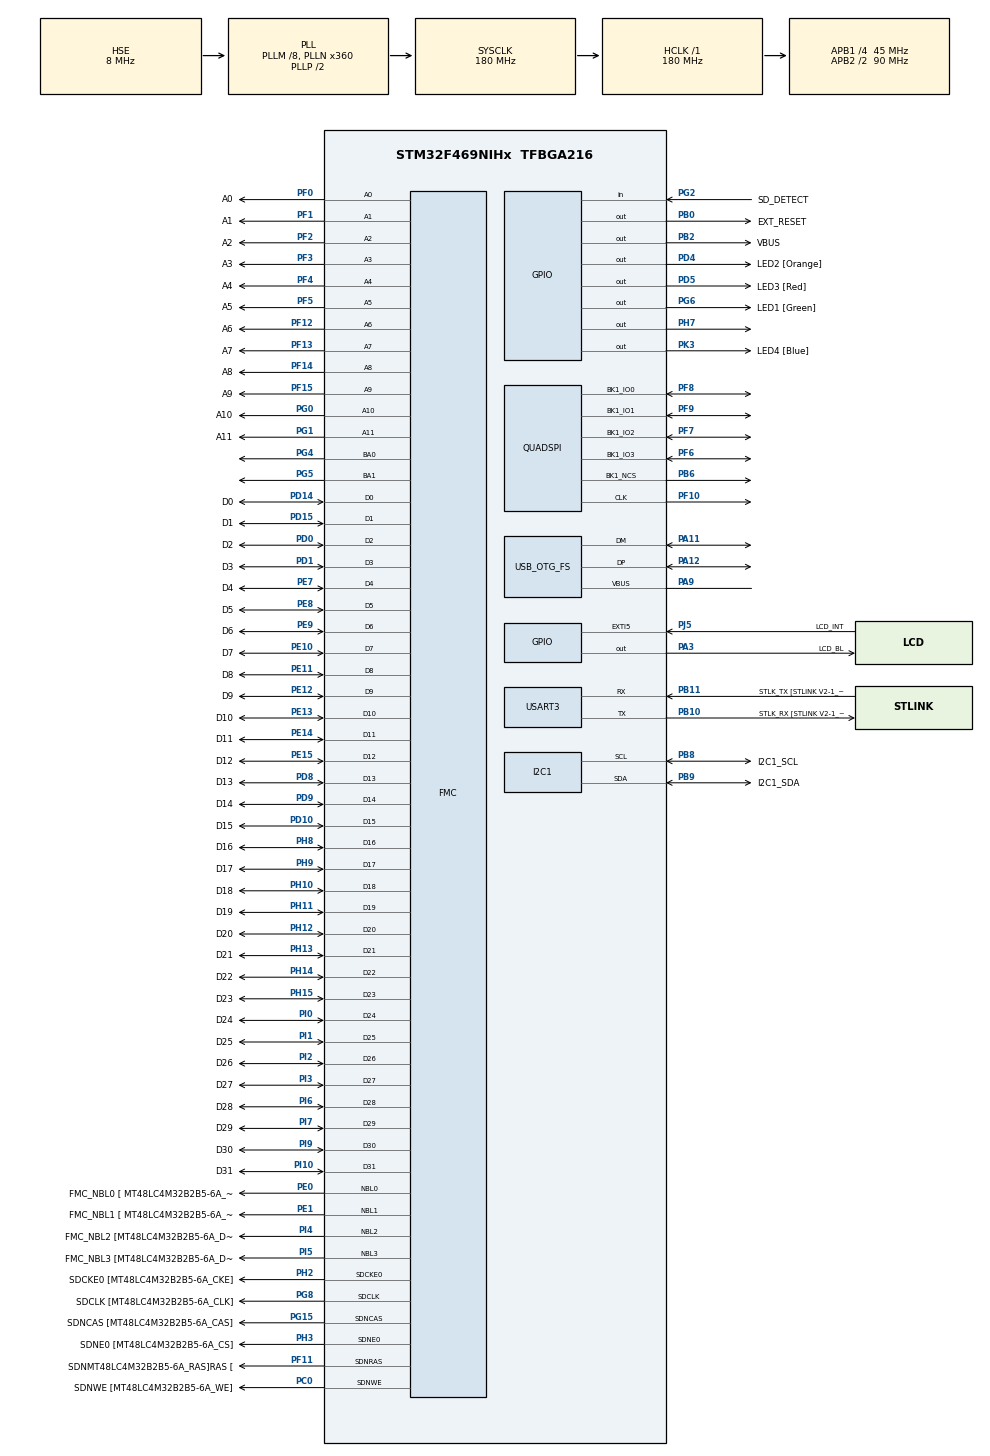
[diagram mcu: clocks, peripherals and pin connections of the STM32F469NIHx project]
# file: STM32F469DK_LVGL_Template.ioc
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DMA2D.ColorMode=DMA2D_OUTPUT_RGB565
DSIHOST.BTA_FlowControl=__NULL
DSIHOST.ClockLaneHS2LPTime=35
DSIHOST.ClockLaneLP2HSTime=35
DSIHOST.DataLaneHS2LPTime=35
DSIHOST.DataLaneLP2HSTime=35
DSIHOST.LPCommandEnable=DSI_LP_COMMAND_ENABLE
DSIHOST.LPHorizontalBackPorchEnable=DSI_LP_HBP_ENABLE
DSIHOST.LPHorizontalFrontPorchEnable=DSI_LP_HFP_ENABLE
DSIHOST.LPLargestPacketSize=16
DSIHOST.LPVerticalActiveEnable=DSI_LP_VACT_ENABLE
DSIHOST.LPVerticalBackPorchEnable=DSI_LP_VBP_ENABLE
DSIHOST.LPVerticalFrontPorchEnable=DSI_LP_VFP_ENABLE
DSIHOST.LPVerticalSyncActiveEnable=DSI_LP_VSYNC_ENABLE
DSIHOST.Mode=DSI_VID_MODE_BURST
DSIHOST.NumberOfLanes=DSI_TWO_DATA_LANES
DSIHOST.PacketSize=800
DSIHOST.StopWaitTime=10
DSIHOST_CKN.GPIO_Label=DSI_CK_N
DSIHOST_CKN.Mode=DSIHost_Video
DSIHOST_CKN.Signal=DSIHOST_CKN
DSIHOST_CKP.GPIO_Label=DSI_CK_P
DSIHOST_CKP.Mode=DSIHost_Video
DSIHOST_CKP.Signal=DSIHOST_CKP
DSIHOST_D0N.GPIO_Label=DSI_D0_N
DSIHOST_D0N.Mode=DSIHost_Video
DSIHOST_D0N.Signal=DSIHOST_D0N
DSIHOST_D0P.GPIO_Label=DSI_D0_P
DSIHOST_D0P.Mode=DSIHost_Video
DSIHOST_D0P.Signal=DSIHOST_D0P
DSIHOST_D1N.GPIO_Label=DSI_D1_N
DSIHOST_D1N.Mode=DSIHost_Video
DSIHOST_D1N.Signal=DSIHOST_D1N
DSIHOST_D1P.GPIO_Label=DSI_D1_P
DSIHOST_D1P.Mode=DSIHost_Video
DSIHOST_D1P.Signal=DSIHOST_D1P
Dma.MEMTOMEM.0.Direction=DMA_MEMORY_TO_MEMORY
Dma.MEMTOMEM.0.FIFOMode=DMA_FIFOMODE_ENABLE
Dma.MEMTOMEM.0.FIFOThreshold=DMA_FIFO_THRESHOLD_FULL
Dma.MEMTOMEM.0.Instance=DMA2_Stream0
Dma.MEMTOMEM.0.MemBurst=DMA_MBURST_SINGLE
Dma.MEMTOMEM.0.MemDataAlignment=DMA_MDATAALIGN_WORD
Dma.MEMTOMEM.0.MemInc=DMA_MINC_ENABLE
Dma.MEMTOMEM.0.Mode=DMA_NORMAL
Dma.MEMTOMEM.0.PeriphBurst=DMA_PBURST_SINGLE
Dma.MEMTOMEM.0.PeriphDataAlignment=DMA_PDATAALIGN_WORD
Dma.MEMTOMEM.0.PeriphInc=DMA_PINC_ENABLE
Dma.MEMTOMEM.0.Priority=DMA_PRIORITY_LOW
Dma.Request0=MEMTOMEM
FATFS._FS_EXFAT=1
FATFS._FS_TINY=0
FATFS._MAX_SS=4096
FATFS._USE_LFN=2
FATFS._USE_MUTEX=0
FMC.CASLatency1=FMC_SDRAM_CAS_LATENCY_3
FMC.ExitSelfRefreshDelay1=7
FMC.LoadToActiveDelay1=2
FMC.RCDDelay1=2
FMC.RPDelay1=2
FMC.RPDelay2=2
FMC.ReadBurst1=FMC_SDRAM_RBURST_ENABLE
FMC.ReadBurst2=FMC_SDRAM_RBURST_ENABLE
FMC.RowCycleDelay1=7
FMC.RowCycleDelay2=7
FMC.SDClockPeriod1=FMC_SDRAM_CLOCK_PERIOD_2
FMC.SDClockPeriod2=FMC_SDRAM_CLOCK_PERIOD_2
FMC.SelfRefreshTime1=4
FMC.WriteRecoveryTime1=3
FREERTOS.Tasks01=mainTask,0,2048,MainTask,As weak,NULL,Dynamic,NULL,NULL;gfxTask,-2,1024,GfxTask,As external,NULL,Dynamic,NULL,NULL;rtTask,3,256,RTTask,As external,NULL,Dynamic,NULL,NULL
FREERTOS.configMINIMAL_STACK_SIZE=256
FREERTOS.configTOTAL_HEAP_SIZE=32787
FREERTOS.configUSE_NEWLIB_REENTRANT=1
LTDC.ActiveW=800
LTDC.Alpha_L0=255
LTDC.BlendingFactor1_L0=LTDC_BLENDING_FACTOR1_PAxCA
LTDC.BlendingFactor2_L0=LTDC_BLENDING_FACTOR2_PAxCA
LTDC.FBStartAdress_L0=0xC0000000
LTDC.HBP=34
LTDC.HFP=34
LTDC.HSPolarity=LTDC_HSPOLARITY_AH
LTDC.HSync=2
LTDC.ImageHeight_L0=480
LTDC.ImageWidth_L0=800
LTDC.Layers=0
LTDC.PixelFormat_L0=LTDC_PIXEL_FORMAT_RGB565
LTDC.VBP=150
LTDC.VFP=150
LTDC.VSPolarity=LTDC_VSPOLARITY_AH
LTDC.VSync=120
LTDC.WindowX1_L0=800
LTDC.WindowY1_L0=480
Mcu.Family=STM32F4
Mcu.Name=STM32F469NIHx
Mcu.Package=TFBGA216
NVIC.DMA2D_IRQn=true\:5\:0\:false\:false\:true\:true\:true\:true\:true
NVIC.DMA2_Stream0_IRQn=true\:5\:0\:false\:false\:true\:true\:true\:true\:true
NVIC.DSI_IRQn=true\:5\:0\:false\:false\:true\:true\:true\:true\:true
NVIC.LTDC_IRQn=true\:5\:0\:false\:false\:true\:true\:true\:true\:true
NVIC.OTG_FS_IRQn=true\:5\:0\:false\:false\:true\:true\:true\:true\:true
NVIC.PriorityGroup=NVIC_PRIORITYGROUP_4
NVIC.TIM7_IRQn=true\:3\:0\:true\:false\:true\:false\:false\:true\:true
NVIC.TimeBase=TIM7_IRQn
NVIC.TimeBaseIP=TIM7
PA0/WKUP.GPIO_Label=WAKEUP [B2]
PA0/WKUP.Mode=SYS_WakeUp0
PA0/WKUP.Signal=SYS_WKUP
PA11.Mode=Host_Only
PA11.Signal=USB_OTG_FS_DM
PA12.Mode=Host_Only
PA12.Signal=USB_OTG_FS_DP
PA13.GPIO_Label=SWDIO
PA13.Mode=Serial_Wire
PA13.Signal=SYS_JTMS-SWDIO
PA14.GPIO_Label=SWCLK
PA14.Mode=Serial_Wire
PA14.Signal=SYS_JTCK-SWCLK
PA3.GPIO_Label=LCD_BL
PA3.Signal=GPIO_Output
PA9.Mode=Activate_VBUS
PA9.Signal=USB_OTG_FS_VBUS
PB0.GPIO_Label=EXT_RESET
PB0.GPIO_ModeDefaultOutputPP=GPIO_MODE_OUTPUT_PP
PB0.GPIO_PuPd=GPIO_NOPULL
PB0.GPIO_Speed=GPIO_SPEED_FREQ_LOW
PB0.Signal=GPIO_Output
PB10.GPIO_Label=STLK_RX [STLINK V2-1_U2_RX]
PB10.GPIO_Mode=GPIO_MODE_AF_PP
PB10.GPIO_PuPd=GPIO_PULLUP
PB10.GPIO_Speed=GPIO_SPEED_FREQ_VERY_HIGH
PB10.Mode=Asynchronous
PB10.Signal=USART3_TX
PB11.GPIO_Label=STLK_TX [STLINK V2-1_U2_TX]
PB11.GPIO_Mode=GPIO_MODE_AF_PP
PB11.GPIO_PuPd=GPIO_PULLUP
PB11.GPIO_Speed=GPIO_SPEED_FREQ_VERY_HIGH
PB11.Mode=Asynchronous
PB11.Signal=USART3_RX
PB2/BOOT1.GPIO_Label=VBUS
PB2/BOOT1.GPIO_ModeDefaultOutputPP=GPIO_MODE_OUTPUT_PP
PB2/BOOT1.GPIO_PuPd=GPIO_NOPULL
PB2/BOOT1.GPIO_Speed=GPIO_SPEED_FREQ_LOW
PB2/BOOT1.PinState=GPIO_PIN_SET
PB2/BOOT1.Signal=GPIO_Output
PB6.Mode=Single Bank 1
PB6.Signal=QUADSPI_BK1_NCS
PB8.GPIO_Label=I2C1_SCL
PB8.GPIO_Mode=GPIO_MODE_AF_OD
PB8.GPIO_Pu=GPIO_PULLUP
PB8.GPIO_Speed=GPIO_SPEED_FREQ_VERY_HIGH
PB8.Mode=I2C
PB8.Signal=I2C1_SCL
PB9.GPIO_Label=I2C1_SDA
PB9.GPIO_Mode=GPIO_MODE_AF_OD
PB9.GPIO_Pu=GPIO_PULLUP
PB9.GPIO_Speed=GPIO_SPEED_FREQ_VERY_HIGH
PB9.Mode=I2C
PB9.Signal=I2C1_SDA
PC0.GPIO_Label=SDNWE [MT48LC4M32B2B5-6A_WE]
PC0.GPIO_Mode=GPIO_MODE_AF_PP
PC0.GPIO_PuPd=GPIO_NOPULL
PC0.GPIO_Speed_High_Default=GPIO_SPEED_FREQ_VERY_HIGH
PC0.Signal=FMC_SDNWE
PC14/OSC32_IN.Mode=LSE-External-Oscillator
PC14/OSC32_IN.Signal=RCC_OSC32_IN
PC15/OSC32_OUT.Mode=LSE-External-Oscillator
PC15/OSC32_OUT.Signal=RCC_OSC32_OUT
PD0.GPIO_Label=D2
PD0.GPIO_Mode=GPIO_MODE_AF_PP
PD0.GPIO_PuPd=GPIO_NOPULL
PD0.GPIO_Speed_High_Default=GPIO_SPEED_FREQ_VERY_HIGH
PD0.Signal=FMC_D2_DA2
PD1.GPIO_Label=D3
PD1.GPIO_Mode=GPIO_MODE_AF_PP
PD1.GPIO_PuPd=GPIO_NOPULL
PD1.GPIO_Speed_High_Default=GPIO_SPEED_FREQ_VERY_HIGH
PD1.Signal=FMC_D3_DA3
PD10.GPIO_Label=D15
PD10.GPIO_Mode=GPIO_MODE_AF_PP
PD10.GPIO_PuPd=GPIO_NOPULL
PD10.GPIO_Speed_High_Default=GPIO_SPEED_FREQ_VERY_HIGH
PD10.Signal=FMC_D15_DA15
PD14.GPIO_Label=D0
PD14.GPIO_Mode=GPIO_MODE_AF_PP
PD14.GPIO_PuPd=GPIO_NOPULL
PD14.GPIO_Speed_High_Default=GPIO_SPEED_FREQ_VERY_HIGH
PD14.Signal=FMC_D0_DA0
PD15.GPIO_Label=D1
PD15.GPIO_Mode=GPIO_MODE_AF_PP
PD15.GPIO_PuPd=GPIO_NOPULL
PD15.GPIO_Speed_High_Default=GPIO_SPEED_FREQ_VERY_HIGH
PD15.Signal=FMC_D1_DA1
PD4.GPIO_Label=LED2 [Orange]
PD4.GPIO_ModeDefaultOutputPP=GPIO_MODE_OUTPUT_OD
PD4.GPIO_PuPd=GPIO_NOPULL
PD4.GPIO_Speed=GPIO_SPEED_FREQ_LOW
PD4.Signal=GPIO_Output
PD5.GPIO_Label=LED3 [Red]
PD5.GPIO_ModeDefaultOutputPP=GPIO_MODE_OUTPUT_OD
PD5.GPIO_PuPd=GPIO_NOPULL
PD5.GPIO_Speed=GPIO_SPEED_FREQ_LOW
PD5.Signal=GPIO_Output
PD8.GPIO_Label=D13
PD8.GPIO_Mode=GPIO_MODE_AF_PP
PD8.GPIO_PuPd=GPIO_NOPULL
PD8.GPIO_Speed_High_Default=GPIO_SPEED_FREQ_VERY_HIGH
PD8.Signal=FMC_D13_DA13
PD9.GPIO_Label=D14
PD9.GPIO_Mode=GPIO_MODE_AF_PP
PD9.GPIO_PuPd=GPIO_NOPULL
PD9.GPIO_Speed_High_Default=GPIO_SPEED_FREQ_VERY_HIGH
PD9.Signal=FMC_D14_DA14
PE0.GPIO_Label=FMC_NBL0 [ MT48LC4M32B2B5-6A_DQM0]
PE0.GPIO_Mode=GPIO_MODE_AF_PP
PE0.GPIO_PuPd=GPIO_NOPULL
PE0.GPIO_Speed_High_Default=GPIO_SPEED_FREQ_VERY_HIGH
PE0.Signal=FMC_NBL0
PE1.GPIO_Label=FMC_NBL1 [ MT48LC4M32B2B5-6A_DQM1]
PE1.GPIO_Mode=GPIO_MODE_AF_PP
PE1.GPIO_PuPd=GPIO_NOPULL
PE1.GPIO_Speed_High_Default=GPIO_SPEED_FREQ_VERY_HIGH
PE1.Signal=FMC_NBL1
PE10.GPIO_Label=D7
PE10.GPIO_Mode=GPIO_MODE_AF_PP
PE10.GPIO_PuPd=GPIO_NOPULL
PE10.GPIO_Speed_High_Default=GPIO_SPEED_FREQ_VERY_HIGH
PE10.Signal=FMC_D7_DA7
PE11.GPIO_Label=D8
PE11.GPIO_Mode=GPIO_MODE_AF_PP
PE11.GPIO_PuPd=GPIO_NOPULL
PE11.GPIO_Speed_High_Default=GPIO_SPEED_FREQ_VERY_HIGH
PE11.Signal=FMC_D8_DA8
PE12.GPIO_Label=D9
PE12.GPIO_Mode=GPIO_MODE_AF_PP
PE12.GPIO_PuPd=GPIO_NOPULL
PE12.GPIO_Speed_High_Default=GPIO_SPEED_FREQ_VERY_HIGH
PE12.Signal=FMC_D9_DA9
PE13.GPIO_Label=D10
PE13.GPIO_Mode=GPIO_MODE_AF_PP
PE13.GPIO_PuPd=GPIO_NOPULL
PE13.GPIO_Speed_High_Default=GPIO_SPEED_FREQ_VERY_HIGH
PE13.Signal=FMC_D10_DA10
PE14.GPIO_Label=D11
PE14.GPIO_Mode=GPIO_MODE_AF_PP
PE14.GPIO_PuPd=GPIO_NOPULL
PE14.GPIO_Speed_High_Default=GPIO_SPEED_FREQ_VERY_HIGH
PE14.Signal=FMC_D11_DA11
PE15.GPIO_Label=D12
PE15.GPIO_Mode=GPIO_MODE_AF_PP
PE15.GPIO_PuPd=GPIO_NOPULL
PE15.GPIO_Speed_High_Default=GPIO_SPEED_FREQ_VERY_HIGH
PE15.Signal=FMC_D12_DA12
PE7.GPIO_Label=D4
PE7.GPIO_Mode=GPIO_MODE_AF_PP
PE7.GPIO_PuPd=GPIO_NOPULL
PE7.GPIO_Speed_High_Default=GPIO_SPEED_FREQ_VERY_HIGH
PE7.Signal=FMC_D4_DA4
PE8.GPIO_Label=D5
PE8.GPIO_Mode=GPIO_MODE_AF_PP
PE8.GPIO_PuPd=GPIO_NOPULL
PE8.GPIO_Speed_High_Default=GPIO_SPEED_FREQ_VERY_HIGH
PE8.Signal=FMC_D5_DA5
PE9.GPIO_Label=D6
PE9.GPIO_Mode=GPIO_MODE_AF_PP
PE9.GPIO_PuPd=GPIO_NOPULL
PE9.GPIO_Speed_High_Default=GPIO_SPEED_FREQ_VERY_HIGH
PE9.Signal=FMC_D6_DA6
PF0.GPIO_Label=A0
PF0.GPIO_Mode=GPIO_MODE_AF_PP
PF0.GPIO_PuPd=GPIO_NOPULL
PF0.GPIO_Speed_High_Default=GPIO_SPEED_FREQ_VERY_HIGH
PF0.Signal=FMC_A0
PF1.GPIO_Label=A1
PF1.GPIO_Mode=GPIO_MODE_AF_PP
PF1.GPIO_PuPd=GPIO_NOPULL
PF1.GPIO_Speed_High_Default=GPIO_SPEED_FREQ_VERY_HIGH
PF1.Signal=FMC_A1
PF10.Mode=Single Bank 1
PF10.Signal=QUADSPI_CLK
PF11.GPIO_Label=SDNMT48LC4M32B2B5-6A_RAS]RAS [
PF11.GPIO_Mode=GPIO_MODE_AF_PP
PF11.GPIO_PuPd=GPIO_NOPULL
PF11.GPIO_Speed_High_Default=GPIO_SPEED_FREQ_VERY_HIGH
PF11.Signal=FMC_SDNRAS
PF12.GPIO_Label=A6
PF12.GPIO_Mode=GPIO_MODE_AF_PP
PF12.GPIO_PuPd=GPIO_NOPULL
PF12.GPIO_Speed_High_Default=GPIO_SPEED_FREQ_VERY_HIGH
PF12.Signal=FMC_A6
PF13.GPIO_Label=A7
PF13.GPIO_Mode=GPIO_MODE_AF_PP
PF13.GPIO_PuPd=GPIO_NOPULL
PF13.GPIO_Speed_High_Default=GPIO_SPEED_FREQ_VERY_HIGH
PF13.Signal=FMC_A7
PF14.GPIO_Label=A8
PF14.GPIO_Mode=GPIO_MODE_AF_PP
PF14.GPIO_PuPd=GPIO_NOPULL
PF14.GPIO_Speed_High_Default=GPIO_SPEED_FREQ_VERY_HIGH
PF14.Signal=FMC_A8
PF15.GPIO_Label=A9
PF15.GPIO_Mode=GPIO_MODE_AF_PP
PF15.GPIO_PuPd=GPIO_NOPULL
PF15.GPIO_Speed_High_Default=GPIO_SPEED_FREQ_VERY_HIGH
PF15.Signal=FMC_A9
PF2.GPIO_Label=A2
PF2.GPIO_Mode=GPIO_MODE_AF_PP
PF2.GPIO_PuPd=GPIO_NOPULL
PF2.GPIO_Speed_High_Default=GPIO_SPEED_FREQ_VERY_HIGH
PF2.Signal=FMC_A2
PF3.GPIO_Label=A3
PF3.GPIO_Mode=GPIO_MODE_AF_PP
PF3.GPIO_PuPd=GPIO_NOPULL
PF3.GPIO_Speed_High_Default=GPIO_SPEED_FREQ_VERY_HIGH
PF3.Signal=FMC_A3
PF4.GPIO_Label=A4
PF4.GPIO_Mode=GPIO_MODE_AF_PP
PF4.GPIO_PuPd=GPIO_NOPULL
PF4.GPIO_Speed_High_Default=GPIO_SPEED_FREQ_VERY_HIGH
PF4.Signal=FMC_A4
PF5.GPIO_Label=A5
PF5.GPIO_Mode=GPIO_MODE_AF_PP
PF5.GPIO_PuPd=GPIO_NOPULL
PF5.GPIO_Speed_High_Default=GPIO_SPEED_FREQ_VERY_HIGH
PF5.Signal=FMC_A5
PF6.Mode=Single Bank 1
PF6.Signal=QUADSPI_BK1_IO3
PF7.Mode=Single Bank 1
PF7.Signal=QUADSPI_BK1_IO2
PF8.Mode=Single Bank 1
PF8.Signal=QUADSPI_BK1_IO0
PF9.Mode=Single Bank 1
PF9.Signal=QUADSPI_BK1_IO1
PG0.GPIO_Label=A10
PG0.GPIO_Mode=GPIO_MODE_AF_PP
PG0.GPIO_PuPd=GPIO_NOPULL
PG0.GPIO_Speed_High_Default=GPIO_SPEED_FREQ_VERY_HIGH
PG0.Signal=FMC_A10
PG1.GPIO_Label=A11
PG1.GPIO_Mode=GPIO_MODE_AF_PP
PG1.GPIO_PuPd=GPIO_NOPULL
PG1.GPIO_Speed_High_Default=GPIO_SPEED_FREQ_VERY_HIGH
PG1.Signal=FMC_A11
PG15.GPIO_Label=SDNCAS [MT48LC4M32B2B5-6A_CAS]
PG15.GPIO_Mode=GPIO_MODE_AF_PP
PG15.GPIO_PuPd=GPIO_NOPULL
PG15.GPIO_Speed_High_Default=GPIO_SPEED_FREQ_VERY_HIGH
PG15.Signal=FMC_SDNCAS
PG2.GPIO_Label=SD_DETECT
PG2.GPIO_PuPd=GPIO_PULLUP
PG2.Signal=GPIO_Input
PG4.Signal=FMC_A14_BA0
PG5.Signal=FMC_A15_BA1
PG6.GPIO_Label=LED1 [Green]
PG6.GPIO_ModeDefaultOutputPP=GPIO_MODE_OUTPUT_OD
PG6.GPIO_PuPd=GPIO_NOPULL
PG6.GPIO_Speed=GPIO_SPEED_FREQ_LOW
PG6.Signal=GPIO_Output
PG8.GPIO_Label=SDCLK [MT48LC4M32B2B5-6A_CLK]
PG8.GPIO_Mode=GPIO_MODE_AF_PP
PG8.GPIO_PuPd=GPIO_NOPULL
PG8.GPIO_Speed_High_Default=GPIO_SPEED_FREQ_VERY_HIGH
PG8.Signal=FMC_SDCLK
PH0/OSC_IN.Mode=HSE-External-Oscillator
PH0/OSC_IN.Signal=RCC_OSC_IN
PH1/OSC_OUT.Mode=HSE-External-Oscillator
PH1/OSC_OUT.Signal=RCC_OSC_OUT
PH10.GPIO_Label=D18
PH10.GPIO_Mode=GPIO_MODE_AF_PP
PH10.GPIO_PuPd=GPIO_NOPULL
PH10.GPIO_Speed_High_Default=GPIO_SPEED_FREQ_VERY_HIGH
PH10.Signal=FMC_D18
PH11.GPIO_Label=D19
PH11.GPIO_Mode=GPIO_MODE_AF_PP
PH11.GPIO_PuPd=GPIO_NOPULL
PH11.GPIO_Speed_High_Default=GPIO_SPEED_FREQ_VERY_HIGH
PH11.Signal=FMC_D19
PH12.GPIO_Label=D20
PH12.GPIO_Mode=GPIO_MODE_AF_PP
PH12.GPIO_PuPd=GPIO_NOPULL
PH12.GPIO_Speed_High_Default=GPIO_SPEED_FREQ_VERY_HIGH
PH12.Signal=FMC_D20
PH13.GPIO_Label=D21
PH13.GPIO_Mode=GPIO_MODE_AF_PP
PH13.GPIO_PuPd=GPIO_NOPULL
PH13.GPIO_Speed_High_Default=GPIO_SPEED_FREQ_VERY_HIGH
PH13.Signal=FMC_D21
PH14.GPIO_Label=D22
PH14.GPIO_Mode=GPIO_MODE_AF_PP
PH14.GPIO_PuPd=GPIO_NOPULL
PH14.GPIO_Speed_High_Default=GPIO_SPEED_FREQ_VERY_HIGH
PH14.Signal=FMC_D22
PH15.GPIO_Label=D23
PH15.GPIO_Mode=GPIO_MODE_AF_PP
PH15.GPIO_PuPd=GPIO_NOPULL
PH15.GPIO_Speed_High_Default=GPIO_SPEED_FREQ_VERY_HIGH
PH15.Signal=FMC_D23
PH2.GPIO_Label=SDCKE0 [MT48LC4M32B2B5-6A_CKE]
PH2.GPIO_Mode=GPIO_MODE_AF_PP
PH2.GPIO_PuPd=GPIO_NOPULL
PH2.GPIO_Speed_High_Default=GPIO_SPEED_FREQ_VERY_HIGH
PH2.Mode=SdramChipSelect1_1
PH2.Signal=FMC_SDCKE0
PH3.GPIO_Label=SDNE0 [MT48LC4M32B2B5-6A_CS]
PH3.GPIO_Mode=GPIO_MODE_AF_PP
PH3.GPIO_PuPd=GPIO_NOPULL
PH3.GPIO_Speed_High_Default=GPIO_SPEED_FREQ_VERY_HIGH
PH3.Mode=SdramChipSelect1_1
PH3.Signal=FMC_SDNE0
PH7.Signal=GPIO_Output
PH8.GPIO_Label=D16
PH8.GPIO_Mode=GPIO_MODE_AF_PP
PH8.GPIO_PuPd=GPIO_NOPULL
PH8.GPIO_Speed_High_Default=GPIO_SPEED_FREQ_VERY_HIGH
PH8.Signal=FMC_D16
PH9.GPIO_Label=D17
PH9.GPIO_Mode=GPIO_MODE_AF_PP
PH9.GPIO_PuPd=GPIO_NOPULL
PH9.GPIO_Speed_High_Default=GPIO_SPEED_FREQ_VERY_HIGH
PH9.Signal=FMC_D17
PI0.GPIO_Label=D24
PI0.GPIO_Mode=GPIO_MODE_AF_PP
PI0.GPIO_PuPd=GPIO_NOPULL
PI0.GPIO_Speed_High_Default=GPIO_SPEED_FREQ_VERY_HIGH
PI0.Signal=FMC_D24
PI1.GPIO_Label=D25
PI1.GPIO_Mode=GPIO_MODE_AF_PP
PI1.GPIO_PuPd=GPIO_NOPULL
PI1.GPIO_Speed_High_Default=GPIO_SPEED_FREQ_VERY_HIGH
PI1.Signal=FMC_D25
PI10.GPIO_Label=D31
PI10.GPIO_Mode=GPIO_MODE_AF_PP
PI10.GPIO_PuPd=GPIO_NOPULL
PI10.GPIO_Speed_High_Default=GPIO_SPEED_FREQ_VERY_HIGH
PI10.Signal=FMC_D31
PI2.GPIO_Label=D26
PI2.GPIO_Mode=GPIO_MODE_AF_PP
PI2.GPIO_PuPd=GPIO_NOPULL
PI2.GPIO_Speed_High_Default=GPIO_SPEED_FREQ_VERY_HIGH
PI2.Signal=FMC_D26
PI3.GPIO_Label=D27
PI3.GPIO_Mode=GPIO_MODE_AF_PP
PI3.GPIO_PuPd=GPIO_NOPULL
PI3.GPIO_Speed_High_Default=GPIO_SPEED_FREQ_VERY_HIGH
PI3.Signal=FMC_D27
PI4.GPIO_Label=FMC_NBL2 [MT48LC4M32B2B5-6A_DQM2]
PI4.GPIO_Mode=GPIO_MODE_AF_PP
PI4.GPIO_PuPd=GPIO_NOPULL
PI4.GPIO_Speed_High_Default=GPIO_SPEED_FREQ_VERY_HIGH
PI4.Signal=FMC_NBL2
PI5.GPIO_Label=FMC_NBL3 [MT48LC4M32B2B5-6A_DQM3]
PI5.GPIO_Mode=GPIO_MODE_AF_PP
PI5.GPIO_PuPd=GPIO_NOPULL
PI5.GPIO_Speed_High_Default=GPIO_SPEED_FREQ_VERY_HIGH
PI5.Signal=FMC_NBL3
PI6.GPIO_Label=D28
PI6.GPIO_Mode=GPIO_MODE_AF_PP
PI6.GPIO_PuPd=GPIO_NOPULL
PI6.GPIO_Speed_High_Default=GPIO_SPEED_FREQ_VERY_HIGH
PI6.Signal=FMC_D28
PI7.GPIO_Label=D29
PI7.GPIO_Mode=GPIO_MODE_AF_PP
PI7.GPIO_PuPd=GPIO_NOPULL
PI7.GPIO_Speed_High_Default=GPIO_SPEED_FREQ_VERY_HIGH
PI7.Signal=FMC_D29
PI9.GPIO_Label=D30
PI9.GPIO_Mode=GPIO_MODE_AF_PP
PI9.GPIO_PuPd=GPIO_NOPULL
PI9.GPIO_Speed_High_Default=GPIO_SPEED_FREQ_VERY_HIGH
PI9.Signal=FMC_D30
PJ2.GPIO_Label=DSI_TE
PJ2.GPIO_Mode=GPIO_MODE_AF_PP
PJ2.GPIO_PuPd=GPIO_NOPULL
PJ2.GPIO_Speed=GPIO_SPEED_FREQ_VERY_HIGH
PJ2.Signal=DSIHOST_TE
PJ5.GPIO_Label=LCD_INT
PJ5.GPIO_ModeDefaultEXTI=GPIO_MODE_IT_RISING
PJ5.GPIO_PuPd=GPIO_NOPULL
PJ5.Signal=GPXTI5
PK3.GPIO_Label=LED4 [Blue]
PK3.GPIO_ModeDefaultOutputPP=GPIO_MODE_OUTPUT_OD
PK3.GPIO_PuPd=GPIO_NOPULL
PK3.GPIO_Speed=GPIO_SPEED_FREQ_LOW
PK3.Signal=GPIO_Output
ProjectManager.HeapSize=0x1000
ProjectManager.StackSize=0x1000
ProjectManager.TargetToolchain=STM32CubeIDE
RCC.AHBFreq_Value=180000000
RCC.APB1CLKDivider=RCC_HCLK_DIV4
RCC.APB1Freq_Value=45000000
RCC.APB1TimFreq_Value=90000000
RCC.APB2CLKDivider=RCC_HCLK_DIV2
RCC.APB2Freq_Value=90000000
RCC.APB2TimFreq_Value=180000000
RCC.CortexFreq_Value=180000000
RCC.HCLKFreq_Value=180000000
RCC.HSE_VALUE=8000000
RCC.PLLDSIIDF=DSI_PLL_IN_DIV2
RCC.PLLDSINDIV=125
RCC.PLLM=8
RCC.PLLN=360
RCC.PLLQ=8
RCC.PLLR=6
RCC.PLLSAIN=384
RCC.PLLSAIP=RCC_PLLSAIP_DIV8
RCC.PLLSAIQ=2
RCC.PLLSAIR=6
RCC.PLLSourceVirtual=RCC_PLLSOURCE_HSE
RCC.SYSCLKFreq_VALUE=180000000
RCC.SYSCLKSource=RCC_SYSCLKSOURCE_PLLCLK
RCC.USBCLockSelection=RCC_CLK48CLKSOURCE_PLLSAIP
RCC.USBFreq_Value=48000000
RCC.VCOOutputFreq_Value=360000000
SH.FMC_A0.0=FMC_A0,12b-sda1
SH.FMC_A1.0=FMC_A1,12b-sda1
SH.FMC_A10.0=FMC_A10,12b-sda1
SH.FMC_A11.0=FMC_A11,12b-sda1
SH.FMC_A14_BA0.0=FMC_BA0,FourSdramBanks1
SH.FMC_A15_BA1.0=FMC_BA1,FourSdramBanks1
SH.FMC_A2.0=FMC_A2,12b-sda1
SH.FMC_A3.0=FMC_A3,12b-sda1
SH.FMC_A4.0=FMC_A4,12b-sda1
SH.FMC_A5.0=FMC_A5,12b-sda1
SH.FMC_A6.0=FMC_A6,12b-sda1
SH.FMC_A7.0=FMC_A7,12b-sda1
SH.FMC_A8.0=FMC_A8,12b-sda1
SH.FMC_A9.0=FMC_A9,12b-sda1
SH.FMC_D0_DA0.0=FMC_D0,sd-32b-d1
SH.FMC_D10_DA10.0=FMC_D10,sd-32b-d1
SH.FMC_D11_DA11.0=FMC_D11,sd-32b-d1
SH.FMC_D12_DA12.0=FMC_D12,sd-32b-d1
SH.FMC_D13_DA13.0=FMC_D13,sd-32b-d1
SH.FMC_D14_DA14.0=FMC_D14,sd-32b-d1
SH.FMC_D15_DA15.0=FMC_D15,sd-32b-d1
SH.FMC_D16.0=FMC_D16,sd-32b-d1
SH.FMC_D17.0=FMC_D17,sd-32b-d1
SH.FMC_D18.0=FMC_D18,sd-32b-d1
SH.FMC_D19.0=FMC_D19,sd-32b-d1
SH.FMC_D1_DA1.0=FMC_D1,sd-32b-d1
SH.FMC_D20.0=FMC_D20,sd-32b-d1
SH.FMC_D21.0=FMC_D21,sd-32b-d1
SH.FMC_D22.0=FMC_D22,sd-32b-d1
SH.FMC_D23.0=FMC_D23,sd-32b-d1
SH.FMC_D24.0=FMC_D24,sd-32b-d1
SH.FMC_D25.0=FMC_D25,sd-32b-d1
SH.FMC_D26.0=FMC_D26,sd-32b-d1
SH.FMC_D27.0=FMC_D27,sd-32b-d1
SH.FMC_D28.0=FMC_D28,sd-32b-d1
SH.FMC_D29.0=FMC_D29,sd-32b-d1
SH.FMC_D2_DA2.0=FMC_D2,sd-32b-d1
SH.FMC_D30.0=FMC_D30,sd-32b-d1
SH.FMC_D31.0=FMC_D31,sd-32b-d1
SH.FMC_D3_DA3.0=FMC_D3,sd-32b-d1
SH.FMC_D4_DA4.0=FMC_D4,sd-32b-d1
SH.FMC_D5_DA5.0=FMC_D5,sd-32b-d1
SH.FMC_D6_DA6.0=FMC_D6,sd-32b-d1
SH.FMC_D7_DA7.0=FMC_D7,sd-32b-d1
SH.FMC_D8_DA8.0=FMC_D8,sd-32b-d1
SH.FMC_D9_DA9.0=FMC_D9,sd-32b-d1
SH.FMC_NBL0.0=FMC_NBL0,Sd4ByteEnable1
SH.FMC_NBL1.0=FMC_NBL1,Sd4ByteEnable1
SH.FMC_NBL2.0=FMC_NBL2,Sd4ByteEnable1
SH.FMC_NBL3.0=FMC_NBL3,Sd4ByteEnable1
SH.FMC_SDCLK.0=FMC_SDCLK,12b-sda1
SH.FMC_SDNCAS.0=FMC_SDNCAS,12b-sda1
SH.FMC_SDNRAS.0=FMC_SDNRAS,12b-sda1
SH.FMC_SDNWE.0=FMC_SDNWE,12b-sda1
USART3.VirtualMode=VM_ASYNC
USB_HOST.BSP.number=1
USB_HOST.USBH_HandleTypeDef-MSC_FS=hUsbHostFS
USB_HOST.VirtualModeFS=Msc
USB_HOST0.BSP.STBoard=false
USB_HOST0.BSP.api=Unknown
USB_HOST0.BSP.instance=PB2/BOOT1
USB_HOST0.BSP.ip=GPIO
USB_HOST0.BSP.mode=Output
USB_HOST0.BSP.name=Drive_VBUS_FS
USB_HOST0.BSP.solution=PB2/BOOT1
USB_OTG_FS.Sof_enable=DISABLE
USB_OTG_FS.VirtualMode=Host_Only
USB_OTG_FS.phy_itface=HCD_PHY_EMBEDDED
VP_DMA2D_VS_DMA2D.Mode=DMA2D_Activate
VP_FATFS_VS_USB.Mode=USB
VP_FREERTOS_VS_CMSIS_V1.Mode=CMSIS_V1
VP_LTDC_DSIMode.Mode=RGB888
VP_SYS_VS_tim7.Mode=TIM7
VP_USB_HOST_VS_USB_HOST_MSC_FS.Mode=MSC_FS
board=STM32F469I-DISCO

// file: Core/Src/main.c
/* USER CODE BEGIN Header */
/**
  ******************************************************************************
  * @file           : main.c
  * @brief          : Main program body
  ******************************************************************************
  * @attention
  *
  * Copyright (c) 2023 STMicroelectronics.
  * All rights reserved.
  *
  * This software is licensed under terms that can be found in the LICENSE file
  * in the root directory of this software component.
  * If no LICENSE file comes with this software, it is provided AS-IS.
  *
  ******************************************************************************
  */
/* USER CODE END Header */
#include "main.h"
#include "cmsis_os.h"
#include "fatfs.h"
#include "usb_host.h"

/* USER CODE BEGIN Includes */
#include <stdlib.h>
#include <stdio.h>
#include <lvgl.h>
#include "ui.h"
#include "stm32469i_discovery_qspi.h"
#include <screen_driver.h>
#include <touch_sensor_driver.h>
#include "stm32469i_discovery_sdram.h"
#include "mainTask.h"
#include "gfxTask.h"
#include "rtTask.h"
#include "fatfs.h"
#include "usbh_diskio.h"

/* USER CODE END Includes */

/* USER CODE BEGIN PD */
#define USE_FULL_ASSERT
/**
  * @brief  FMC SDRAM Mode definition register defines
  *
  * @brief  defines copied from the STM32F469I-Disco Board support package
  */
#define SDRAM_MODEREG_BURST_LENGTH_1             ((uint16_t)0x0000)
#define SDRAM_MODEREG_BURST_LENGTH_2             ((uint16_t)0x0001)
#define SDRAM_MODEREG_BURST_LENGTH_4             ((uint16_t)0x0002)
#define SDRAM_MODEREG_BURST_LENGTH_8             ((uint16_t)0x0004)
#define SDRAM_MODEREG_BURST_TYPE_SEQUENTIAL      ((uint16_t)0x0000)
#define SDRAM_MODEREG_BURST_TYPE_INTERLEAVED     ((uint16_t)0x0008)
#define SDRAM_MODEREG_CAS_LATENCY_2              ((uint16_t)0x0020)
#define SDRAM_MODEREG_CAS_LATENCY_3              ((uint16_t)0x0030)
#define SDRAM_MODEREG_OPERATING_MODE_STANDARD    ((uint16_t)0x0000)
#define SDRAM_MODEREG_WRITEBURST_MODE_PROGRAMMED ((uint16_t)0x0000)
#define SDRAM_MODEREG_WRITEBURST_MODE_SINGLE     ((uint16_t)0x0200)

/**
  * @brief  SDRAM refresh counter (90 MHz SD clock)
  *
  * @brief  defines copied from the STM32F469I-Disco Board support package
  */
#define REFRESH_COUNT       ((uint32_t)0x0569)
#define SDRAM_TIMEOUT       ((uint32_t)0xFFFF)

/* USER CODE END PD */

DMA2D_HandleTypeDef hdma2d;

DSI_HandleTypeDef hdsi;

I2C_HandleTypeDef hi2c1;

LTDC_HandleTypeDef hltdc;

QSPI_HandleTypeDef hqspi;

UART_HandleTypeDef huart3;

DMA_HandleTypeDef hdma_memtomem_dma2_stream0;
SDRAM_HandleTypeDef hsdram1;

osThreadId mainTaskHandle;
osThreadId gfxTaskHandle;
osThreadId rtTaskHandle;

void SystemClock_Config(void);
void PeriphCommonClock_Config(void);
static void MX_GPIO_Init(void);
static void MX_DMA_Init(void);
static void MX_DMA2D_Init(void);
static void MX_DSIHOST_DSI_Init(void);
static void MX_FMC_Init(void);
static void MX_I2C1_Init(void);
static void MX_LTDC_Init(void);
static void MX_USART3_UART_Init(void);
static void MX_QUADSPI_Init(void);
void MainTask(void const * argument);
extern void GfxTask(void const * argument);
extern void RTTask(void const * argument);

int main(void)
{

  /* MCU Configuration--------------------------------------------------------*/

  /* Reset of all peripherals, Initializes the Flash interface and the Systick. */
  HAL_Init();

  /* Configure the system clock */
  SystemClock_Config();

/* Configure the peripherals common clocks */
  PeriphCommonClock_Config();

  /* Initialize all configured peripherals */
  MX_GPIO_Init();
  MX_DMA_Init();
  MX_DMA2D_Init();
  MX_DSIHOST_DSI_Init();
  MX_FMC_Init();
  MX_I2C1_Init();
  MX_LTDC_Init();
  MX_USART3_UART_Init();
  MX_QUADSPI_Init();
  MX_FATFS_Init();
  /* USER CODE BEGIN 2 */

  BSP_SDRAM_Init();
  BSP_QSPI_Init();
  BSP_QSPI_EnableMemoryMappedMode();

  lv_init();

  screen_driver_init();
  touch_sensor_driver_init();
  ui_init();

  /* USER CODE END 2 */

  /* Create the thread(s) */
  /* definition and creation of mainTask */
  osThreadDef(mainTask, MainTask, osPriorityNormal, 0, 2048);
  mainTaskHandle = osThreadCreate(osThread(mainTask), NULL);

  /* definition and creation of gfxTask */
  osThreadDef(gfxTask, GfxTask, osPriorityLow, 0, 1024);
  gfxTaskHandle = osThreadCreate(osThread(gfxTask), NULL);

  /* definition and creation of rtTask */
  osThreadDef(rtTask, RTTask, osPriorityRealtime, 0, 256);
  rtTaskHandle = osThreadCreate(osThread(rtTask), NULL);

  /* Start scheduler */
  osKernelStart();
  /* We should never get here as control is now taken by the scheduler */
  /* Infinite loop */
  /* USER CODE BEGIN WHILE */
  while (1)
  {
	  HAL_Delay(5);
    /* USER CODE END WHILE */

  }
}

void SystemClock_Config(void)
{
  RCC_OscInitTypeDef RCC_OscInitStruct = {0};
  RCC_ClkInitTypeDef RCC_ClkInitStruct = {0};

  /** Configure the main internal regulator output voltage
  */
  __HAL_RCC_PWR_CLK_ENABLE();
  __HAL_PWR_VOLTAGESCALING_CONFIG(PWR_REGULATOR_VOLTAGE_SCALE1);

  /** Initializes the RCC Oscillators according to the specified parameters
  * in the RCC_OscInitTypeDef structure.
  */
  RCC_OscInitStruct.OscillatorType = RCC_OSCILLATORTYPE_HSE;
  RCC_OscInitStruct.HSEState = RCC_HSE_ON;
  RCC_OscInitStruct.PLL.PLLState = RCC_PLL_ON;
  RCC_OscInitStruct.PLL.PLLSource = RCC_PLLSOURCE_HSE;
  RCC_OscInitStruct.PLL.PLLM = 8;
  RCC_OscInitStruct.PLL.PLLN = 360;
  RCC_OscInitStruct.PLL.PLLP = RCC_PLLP_DIV2;
  RCC_OscInitStruct.PLL.PLLQ = 8;
  RCC_OscInitStruct.PLL.PLLR = 6;
  if (HAL_RCC_OscConfig(&RCC_OscInitStruct) != HAL_OK)
  {
    Error_Handler();
  }

  /** Activate the Over-Drive mode
  */
  if (HAL_PWREx_EnableOverDrive() != HAL_OK)
  {
    Error_Handler();
  }

  /** Initializes the CPU, AHB and APB buses clocks
  */
  RCC_ClkInitStruct.ClockType = RCC_CLOCKTYPE_HCLK|RCC_CLOCKTYPE_SYSCLK
                              |RCC_CLOCKTYPE_PCLK1|RCC_CLOCKTYPE_PCLK2;
  RCC_ClkInitStruct.SYSCLKSource = RCC_SYSCLKSOURCE_PLLCLK;
  RCC_ClkInitStruct.AHBCLKDivider = RCC_SYSCLK_DIV1;
  RCC_ClkInitStruct.APB1CLKDivider = RCC_HCLK_DIV4;
  RCC_ClkInitStruct.APB2CLKDivider = RCC_HCLK_DIV2;

  if (HAL_RCC_ClockConfig(&RCC_ClkInitStruct, FLASH_LATENCY_5) != HAL_OK)
  {
    Error_Handler();
  }
}

void PeriphCommonClock_Config(void)
{
  RCC_PeriphCLKInitTypeDef PeriphClkInitStruct = {0};

  /** Initializes the peripherals clock
  */
  PeriphClkInitStruct.PeriphClockSelection = RCC_PERIPHCLK_CLK48|RCC_PERIPHCLK_LTDC;
  PeriphClkInitStruct.PLLSAI.PLLSAIN = 384;
  PeriphClkInitStruct.PLLSAI.PLLSAIR = 6;
  PeriphClkInitStruct.PLLSAI.PLLSAIP = RCC_PLLSAIP_DIV8;
  PeriphClkInitStruct.PLLSAIDivR = RCC_PLLSAIDIVR_2;
  PeriphClkInitStruct.Clk48ClockSelection = RCC_CLK48CLKSOURCE_PLLSAIP;
  if (HAL_RCCEx_PeriphCLKConfig(&PeriphClkInitStruct) != HAL_OK)
  {
    Error_Handler();
  }
}

static void MX_DMA2D_Init(void)
{

  hdma2d.Instance = DMA2D;
  hdma2d.Init.Mode = DMA2D_M2M;
  hdma2d.Init.ColorMode = DMA2D_OUTPUT_RGB565;
  hdma2d.Init.OutputOffset = 0;
  hdma2d.LayerCfg[1].InputOffset = 0;
  hdma2d.LayerCfg[1].InputColorMode = DMA2D_INPUT_RGB565;
  hdma2d.LayerCfg[1].AlphaMode = DMA2D_NO_MODIF_ALPHA;
  hdma2d.LayerCfg[1].InputAlpha = 0;
  if (HAL_DMA2D_Init(&hdma2d) != HAL_OK)
  {
    Error_Handler();
  }
  if (HAL_DMA2D_ConfigLayer(&hdma2d, 1) != HAL_OK)
  {
    Error_Handler();
  }

}

static void MX_DSIHOST_DSI_Init(void)
{

  DSI_PLLInitTypeDef PLLInit = {0};
  DSI_HOST_TimeoutTypeDef HostTimeouts = {0};
  DSI_PHY_TimerTypeDef PhyTimings = {0};
  DSI_VidCfgTypeDef VidCfg = {0};

  hdsi.Instance = DSI;
  hdsi.Init.AutomaticClockLaneControl = DSI_AUTO_CLK_LANE_CTRL_DISABLE;
  hdsi.Init.TXEscapeCkdiv = 4;
  hdsi.Init.NumberOfLanes = DSI_TWO_DATA_LANES;
  PLLInit.PLLNDIV = 125;
  PLLInit.PLLIDF = DSI_PLL_IN_DIV2;
  PLLInit.PLLODF = DSI_PLL_OUT_DIV1;
  if (HAL_DSI_Init(&hdsi, &PLLInit) != HAL_OK)
  {
    Error_Handler();
  }
  HostTimeouts.TimeoutCkdiv = 1;
  HostTimeouts.HighSpeedTransmissionTimeout = 0;
  HostTimeouts.LowPowerReceptionTimeout = 0;
  HostTimeouts.HighSpeedReadTimeout = 0;
  HostTimeouts.LowPowerReadTimeout = 0;
  HostTimeouts.HighSpeedWriteTimeout = 0;
  HostTimeouts.HighSpeedWritePrespMode = DSI_HS_PM_DISABLE;
  HostTimeouts.LowPowerWriteTimeout = 0;
  HostTimeouts.BTATimeout = 0;
  if (HAL_DSI_ConfigHostTimeouts(&hdsi, &HostTimeouts) != HAL_OK)
  {
    Error_Handler();
  }
  PhyTimings.ClockLaneHS2LPTime = 35;
  PhyTimings.ClockLaneLP2HSTime = 35;
  PhyTimings.DataLaneHS2LPTime = 35;
  PhyTimings.DataLaneLP2HSTime = 35;
  PhyTimings.DataLaneMaxReadTime = 0;
  PhyTimings.StopWaitTime = 10;
  if (HAL_DSI_ConfigPhyTimer(&hdsi, &PhyTimings) != HAL_OK)
  {
    Error_Handler();
  }
  if (HAL_DSI_SetLowPowerRXFilter(&hdsi, 10000) != HAL_OK)
  {
    Error_Handler();
  }
  if (HAL_DSI_ConfigErrorMonitor(&hdsi, HAL_DSI_ERROR_NONE) != HAL_OK)
  {
    Error_Handler();
  }
  VidCfg.VirtualChannelID = 0;
  VidCfg.ColorCoding = DSI_RGB888;
  VidCfg.LooselyPacked = DSI_LOOSELY_PACKED_DISABLE;
  VidCfg.Mode = DSI_VID_MODE_BURST;
  VidCfg.PacketSize = 800;
  VidCfg.NumberOfChunks = 0;
  VidCfg.NullPacketSize = 0;
  VidCfg.HSPolarity = DSI_HSYNC_ACTIVE_HIGH;
  VidCfg.VSPolarity = DSI_VSYNC_ACTIVE_HIGH;
  VidCfg.DEPolarity = DSI_DATA_ENABLE_ACTIVE_HIGH;
  VidCfg.HorizontalSyncActive = 4;
  VidCfg.HorizontalBackPorch = 66;
  VidCfg.HorizontalLine = 1699;
  VidCfg.VerticalSyncActive = 120;
  VidCfg.VerticalBackPorch = 150;
  VidCfg.VerticalFrontPorch = 150;
  VidCfg.VerticalActive = 480;
  VidCfg.LPCommandEnable = DSI_LP_COMMAND_ENABLE;
  VidCfg.LPLargestPacketSize = 16;
  VidCfg.LPVACTLargestPacketSize = 0;
  VidCfg.LPHorizontalFrontPorchEnable = DSI_LP_HFP_ENABLE;
  VidCfg.LPHorizontalBackPorchEnable = DSI_LP_HBP_ENABLE;
  VidCfg.LPVerticalActiveEnable = DSI_LP_VACT_ENABLE;
  VidCfg.LPVerticalFrontPorchEnable = DSI_LP_VFP_ENABLE;
  VidCfg.LPVerticalBackPorchEnable = DSI_LP_VBP_ENABLE;
  VidCfg.LPVerticalSyncActiveEnable = DSI_LP_VSYNC_ENABLE;
  VidCfg.FrameBTAAcknowledgeEnable = DSI_FBTAA_DISABLE;
  if (HAL_DSI_ConfigVideoMode(&hdsi, &VidCfg) != HAL_OK)
  {
    Error_Handler();
  }
  if (HAL_DSI_SetGenericVCID(&hdsi, 0) != HAL_OK)
  {
    Error_Handler();
  }

}

static void MX_I2C1_Init(void)
{

  hi2c1.Instance = I2C1;
  hi2c1.Init.ClockSpeed = 100000;
  hi2c1.Init.DutyCycle = I2C_DUTYCYCLE_2;
  hi2c1.Init.OwnAddress1 = 0;
  hi2c1.Init.AddressingMode = I2C_ADDRESSINGMODE_7BIT;
  hi2c1.Init.DualAddressMode = I2C_DUALADDRESS_DISABLE;
  hi2c1.Init.OwnAddress2 = 0;
  hi2c1.Init.GeneralCallMode = I2C_GENERALCALL_DISABLE;
  hi2c1.Init.NoStretchMode = I2C_NOSTRETCH_DISABLE;
  if (HAL_I2C_Init(&hi2c1) != HAL_OK)
  {
    Error_Handler();
  }

}

static void MX_LTDC_Init(void)
{

  LTDC_LayerCfgTypeDef pLayerCfg = {0};

  hltdc.Instance = LTDC;
  hltdc.Init.HSPolarity = LTDC_HSPOLARITY_AH;
  hltdc.Init.VSPolarity = LTDC_VSPOLARITY_AH;
  hltdc.Init.DEPolarity = LTDC_DEPOLARITY_AL;
  hltdc.Init.PCPolarity = LTDC_PCPOLARITY_IPC;
  hltdc.Init.HorizontalSync = 1;
  hltdc.Init.VerticalSync = 119;
  hltdc.Init.AccumulatedHBP = 35;
  hltdc.Init.AccumulatedVBP = 269;
  hltdc.Init.AccumulatedActiveW = 835;
  hltdc.Init.AccumulatedActiveH = 749;
  hltdc.Init.TotalWidth = 869;
  hltdc.Init.TotalHeigh = 899;
  hltdc.Init.Backcolor.Blue = 0;
  hltdc.Init.Backcolor.Green = 0;
  hltdc.Init.Backcolor.Red = 0;
  if (HAL_LTDC_Init(&hltdc) != HAL_OK)
  {
    Error_Handler();
  }
  pLayerCfg.WindowX0 = 0;
  pLayerCfg.WindowX1 = 800;
  pLayerCfg.WindowY0 = 0;
  pLayerCfg.WindowY1 = 480;
  pLayerCfg.PixelFormat = LTDC_PIXEL_FORMAT_RGB565;
  pLayerCfg.Alpha = 255;
  pLayerCfg.Alpha0 = 0;
  pLayerCfg.BlendingFactor1 = LTDC_BLENDING_FACTOR1_PAxCA;
  pLayerCfg.BlendingFactor2 = LTDC_BLENDING_FACTOR2_PAxCA;
  pLayerCfg.FBStartAdress = 0xC0000000;
  pLayerCfg.ImageWidth = 800;
  pLayerCfg.ImageHeight = 480;
  pLayerCfg.Backcolor.Blue = 0;
  pLayerCfg.Backcolor.Green = 0;
  pLayerCfg.Backcolor.Red = 0;
  if (HAL_LTDC_ConfigLayer(&hltdc, &pLayerCfg, 0) != HAL_OK)
  {
    Error_Handler();
  }

}

static void MX_QUADSPI_Init(void)
{

  /* QUADSPI parameter configuration*/
  hqspi.Instance = QUADSPI;
  hqspi.Init.ClockPrescaler = 255;
  hqspi.Init.FifoThreshold = 1;
  hqspi.Init.SampleShifting = QSPI_SAMPLE_SHIFTING_NONE;
  hqspi.Init.FlashSize = 1;
  hqspi.Init.ChipSelectHighTime = QSPI_CS_HIGH_TIME_1_CYCLE;
  hqspi.Init.ClockMode = QSPI_CLOCK_MODE_0;
  hqspi.Init.FlashID = QSPI_FLASH_ID_1;
  hqspi.Init.DualFlash = QSPI_DUALFLASH_DISABLE;
  if (HAL_QSPI_Init(&hqspi) != HAL_OK)
  {
    Error_Handler();
  }

}

static void MX_USART3_UART_Init(void)
{

  huart3.Instance = USART3;
  huart3.Init.BaudRate = 115200;
  huart3.Init.WordLength = UART_WORDLENGTH_8B;
  huart3.Init.StopBits = UART_STOPBITS_1;
  huart3.Init.Parity = UART_PARITY_NONE;
  huart3.Init.Mode = UART_MODE_TX_RX;
  huart3.Init.HwFlowCtl = UART_HWCONTROL_NONE;
  huart3.Init.OverSampling = UART_OVERSAMPLING_16;
  if (HAL_UART_Init(&huart3) != HAL_OK)
  {
    Error_Handler();
  }

}

static void MX_DMA_Init(void)
{

  /* DMA controller clock enable */
  __HAL_RCC_DMA2_CLK_ENABLE();

  /* Configure DMA request hdma_memtomem_dma2_stream0 on DMA2_Stream0 */
  hdma_memtomem_dma2_stream0.Instance = DMA2_Stream0;
  hdma_memtomem_dma2_stream0.Init.Channel = DMA_CHANNEL_0;
  hdma_memtomem_dma2_stream0.Init.Direction = DMA_MEMORY_TO_MEMORY;
  hdma_memtomem_dma2_stream0.Init.PeriphInc = DMA_PINC_ENABLE;
  hdma_memtomem_dma2_stream0.Init.MemInc = DMA_MINC_ENABLE;
  hdma_memtomem_dma2_stream0.Init.PeriphDataAlignment = DMA_PDATAALIGN_WORD;
  hdma_memtomem_dma2_stream0.Init.MemDataAlignment = DMA_MDATAALIGN_WORD;
  hdma_memtomem_dma2_stream0.Init.Mode = DMA_NORMAL;
  hdma_memtomem_dma2_stream0.Init.Priority = DMA_PRIORITY_LOW;
  hdma_memtomem_dma2_stream0.Init.FIFOMode = DMA_FIFOMODE_ENABLE;
  hdma_memtomem_dma2_stream0.Init.FIFOThreshold = DMA_FIFO_THRESHOLD_FULL;
  hdma_memtomem_dma2_stream0.Init.MemBurst = DMA_MBURST_SINGLE;
  hdma_memtomem_dma2_stream0.Init.PeriphBurst = DMA_PBURST_SINGLE;
  if (HAL_DMA_Init(&hdma_memtomem_dma2_stream0) != HAL_OK)
  {
    Error_Handler( );
  }

  /* DMA interrupt init */
  /* DMA2_Stream0_IRQn interrupt configuration */
  HAL_NVIC_SetPriority(DMA2_Stream0_IRQn, 5, 0);
  HAL_NVIC_EnableIRQ(DMA2_Stream0_IRQn);

}

/* FMC initialization function */
static void MX_FMC_Init(void)
{

  /* USER CODE BEGIN FMC_Init 0 */
  static FMC_SDRAM_CommandTypeDef Command;
  /* USER CODE END FMC_Init 0 */

  FMC_SDRAM_TimingTypeDef SdramTiming = {0};

  /** Perform the SDRAM1 memory initialization sequence
  */
  hsdram1.Instance = FMC_SDRAM_DEVICE;
  /* hsdram1.Init */
  hsdram1.Init.SDBank = FMC_SDRAM_BANK1;
  hsdram1.Init.ColumnBitsNumber = FMC_SDRAM_COLUMN_BITS_NUM_8;
  hsdram1.Init.RowBitsNumber = FMC_SDRAM_ROW_BITS_NUM_12;
  hsdram1.Init.MemoryDataWidth = FMC_SDRAM_MEM_BUS_WIDTH_32;
  hsdram1.Init.InternalBankNumber = FMC_SDRAM_INTERN_BANKS_NUM_4;
  hsdram1.Init.CASLatency = FMC_SDRAM_CAS_LATENCY_3;
  hsdram1.Init.WriteProtection = FMC_SDRAM_WRITE_PROTECTION_DISABLE;
  hsdram1.Init.SDClockPeriod = FMC_SDRAM_CLOCK_PERIOD_2;
  hsdram1.Init.ReadBurst = FMC_SDRAM_RBURST_ENABLE;
  hsdram1.Init.ReadPipeDelay = FMC_SDRAM_RPIPE_DELAY_0;
  /* SdramTiming */
  SdramTiming.LoadToActiveDelay = 2;
  SdramTiming.ExitSelfRefreshDelay = 7;
  SdramTiming.SelfRefreshTime = 4;
  SdramTiming.RowCycleDelay = 7;
  SdramTiming.WriteRecoveryTime = 3;
  SdramTiming.RPDelay = 2;
  SdramTiming.RCDDelay = 2;

  if (HAL_SDRAM_Init(&hsdram1, &SdramTiming) != HAL_OK)
  {
    Error_Handler( );
  }

  /* USER CODE BEGIN FMC_Init 2 */

    /*
     * The following code is copied from the STM32F469I-Disco Board Support Package
     */
    __IO uint32_t tmpmrd = 0;

    /* Step 1: Configure a clock configuration enable command */
    Command.CommandMode            = FMC_SDRAM_CMD_CLK_ENABLE;
    Command.CommandTarget          = FMC_SDRAM_CMD_TARGET_BANK1;
    Command.AutoRefreshNumber      = 1;
    Command.ModeRegisterDefinition = 0;

    /* Send the command */
    HAL_SDRAM_SendCommand(&hsdram1, &Command, SDRAM_TIMEOUT);

    /* Step 2: Insert 100 us minimum delay */
    /* Inserted delay is equal to 1 ms due to systick time base unit (ms) */
    HAL_Delay(1);

    /* Step 3: Configure a PALL (precharge all) command */
    Command.CommandMode            = FMC_SDRAM_CMD_PALL;
    Command.CommandTarget          = FMC_SDRAM_CMD_TARGET_BANK1;
    Command.AutoRefreshNumber      = 1;
    Command.ModeRegisterDefinition = 0;

    /* Send the command */
    HAL_SDRAM_SendCommand(&hsdram1, &Command, SDRAM_TIMEOUT);

    /* Step 4: Configure an Auto Refresh command */
    Command.CommandMode            = FMC_SDRAM_CMD_AUTOREFRESH_MODE;
    Command.CommandTarget          = FMC_SDRAM_CMD_TARGET_BANK1;
    Command.AutoRefreshNumber      = 8;
    Command.ModeRegisterDefinition = 0;

    /* Send the command */
    HAL_SDRAM_SendCommand(&hsdram1, &Command, SDRAM_TIMEOUT);

    /* Step 5: Program the external memory mode register */
    tmpmrd = (uint32_t)SDRAM_MODEREG_BURST_LENGTH_1          |\
                       SDRAM_MODEREG_BURST_TYPE_SEQUENTIAL   |\
                       SDRAM_MODEREG_CAS_LATENCY_3           |\
                       SDRAM_MODEREG_OPERATING_MODE_STANDARD |\
                       SDRAM_MODEREG_WRITEBURST_MODE_SINGLE;

    Command.CommandMode            = FMC_SDRAM_CMD_LOAD_MODE;
    Command.CommandTarget          = FMC_SDRAM_CMD_TARGET_BANK1;
    Command.AutoRefreshNumber      = 1;
    Command.ModeRegisterDefinition = tmpmrd;

    /* Send the command */
    HAL_SDRAM_SendCommand(&hsdram1, &Command, SDRAM_TIMEOUT);

    /* Step 6: Set the refresh rate counter */
    /* Set the device refresh rate */
    HAL_SDRAM_ProgramRefreshRate(&hsdram1, REFRESH_COUNT);

  /* USER CODE END FMC_Init 2 */
}

static void MX_GPIO_Init(void)
{
  GPIO_InitTypeDef GPIO_InitStruct = {0};

  /* GPIO Ports Clock Enable */
  __HAL_RCC_GPIOE_CLK_ENABLE();
  __HAL_RCC_GPIOB_CLK_ENABLE();
  __HAL_RCC_GPIOA_CLK_ENABLE();
  __HAL_RCC_GPIOG_CLK_ENABLE();
  __HAL_RCC_GPIOD_CLK_ENABLE();
  __HAL_RCC_GPIOI_CLK_ENABLE();
  __HAL_RCC_GPIOF_CLK_ENABLE();
  __HAL_RCC_GPIOK_CLK_ENABLE();
  __HAL_RCC_GPIOH_CLK_ENABLE();
  __HAL_RCC_GPIOC_CLK_ENABLE();
  __HAL_RCC_GPIOJ_CLK_ENABLE();

  /*Configure GPIO pin Output Level */
  HAL_GPIO_WritePin(GPIOD, LED3_Pin|LED2_Pin, GPIO_PIN_RESET);

  /*Configure GPIO pin Output Level */
  HAL_GPIO_WritePin(LED4_GPIO_Port, LED4_Pin, GPIO_PIN_RESET);

  /*Configure GPIO pin Output Level */
  HAL_GPIO_WritePin(LED1_GPIO_Port, LED1_Pin, GPIO_PIN_RESET);

  /*Configure GPIO pin Output Level */
  HAL_GPIO_WritePin(VBUS_GPIO_Port, VBUS_Pin, GPIO_PIN_SET);

  /*Configure GPIO pin Output Level */
  HAL_GPIO_WritePin(GPIOH, GPIO_PIN_7, GPIO_PIN_RESET);

  /*Configure GPIO pin Output Level */
  HAL_GPIO_WritePin(LCD_BL_GPIO_Port, LCD_BL_Pin, GPIO_PIN_RESET);

  /*Configure GPIO pin Output Level */
  HAL_GPIO_WritePin(EXT_RESET_GPIO_Port, EXT_RESET_Pin, GPIO_PIN_RESET);

  /*Configure GPIO pins : LED3_Pin LED2_Pin */
  GPIO_InitStruct.Pin = LED3_Pin|LED2_Pin;
  GPIO_InitStruct.Mode = GPIO_MODE_OUTPUT_OD;
  GPIO_InitStruct.Pull = GPIO_NOPULL;
  GPIO_InitStruct.Speed = GPIO_SPEED_FREQ_LOW;
  HAL_GPIO_Init(GPIOD, &GPIO_InitStruct);

  /*Configure GPIO pin : LED4_Pin */
  GPIO_InitStruct.Pin = LED4_Pin;
  GPIO_InitStruct.Mode = GPIO_MODE_OUTPUT_OD;
  GPIO_InitStruct.Pull = GPIO_NOPULL;
  GPIO_InitStruct.Speed = GPIO_SPEED_FREQ_LOW;
  HAL_GPIO_Init(LED4_GPIO_Port, &GPIO_InitStruct);

  /*Configure GPIO pin : LED1_Pin */
  GPIO_InitStruct.Pin = LED1_Pin;
  GPIO_InitStruct.Mode = GPIO_MODE_OUTPUT_OD;
  GPIO_InitStruct.Pull = GPIO_NOPULL;
  GPIO_InitStruct.Speed = GPIO_SPEED_FREQ_LOW;
  HAL_GPIO_Init(LED1_GPIO_Port, &GPIO_InitStruct);

  /*Configure GPIO pins : VBUS_Pin EXT_RESET_Pin */
  GPIO_InitStruct.Pin = VBUS_Pin|EXT_RESET_Pin;
  GPIO_InitStruct.Mode = GPIO_MODE_OUTPUT_PP;
  GPIO_InitStruct.Pull = GPIO_NOPULL;
  GPIO_InitStruct.Speed = GPIO_SPEED_FREQ_LOW;
  HAL_GPIO_Init(GPIOB, &GPIO_InitStruct);

  /*Configure GPIO pin : SD_DETECT_Pin */
  GPIO_InitStruct.Pin = SD_DETECT_Pin;
  GPIO_InitStruct.Mode = GPIO_MODE_INPUT;
  GPIO_InitStruct.Pull = GPIO_PULLUP;
  HAL_GPIO_Init(SD_DETECT_GPIO_Port, &GPIO_InitStruct);

  /*Configure GPIO pin : LCD_INT_Pin */
  GPIO_InitStruct.Pin = LCD_INT_Pin;
  GPIO_InitStruct.Mode = GPIO_MODE_IT_RISING;
  GPIO_InitStruct.Pull = GPIO_NOPULL;
  HAL_GPIO_Init(LCD_INT_GPIO_Port, &GPIO_InitStruct);

  /*Configure GPIO pin : PH7 */
  GPIO_InitStruct.Pin = GPIO_PIN_7;
  GPIO_InitStruct.Mode = GPIO_MODE_OUTPUT_PP;
  GPIO_InitStruct.Pull = GPIO_NOPULL;
  GPIO_InitStruct.Speed = GPIO_SPEED_FREQ_LOW;
  HAL_GPIO_Init(GPIOH, &GPIO_InitStruct);

  /*Configure GPIO pin : LCD_BL_Pin */
  GPIO_InitStruct.Pin = LCD_BL_Pin;
  GPIO_InitStruct.Mode = GPIO_MODE_OUTPUT_PP;
  GPIO_InitStruct.Pull = GPIO_NOPULL;
  GPIO_InitStruct.Speed = GPIO_SPEED_FREQ_LOW;
  HAL_GPIO_Init(LCD_BL_GPIO_Port, &GPIO_InitStruct);

}

/* USER CODE BEGIN 4 */

int _write(int file, char *ptr, int len)
{
  HAL_UART_Transmit(&huart3, (const uint8_t *)ptr, len, 100);
  return len;
}

/* USER CODE END 4 */

__weak void MainTask(void const * argument)
{
  /* init code for USB_HOST */
  MX_USB_HOST_Init();
  for(;;)
  {
    osDelay(1);
  }
}

void HAL_TIM_PeriodElapsedCallback(TIM_HandleTypeDef *htim)
{
  if (htim->Instance == TIM7) {
    HAL_IncTick();
  }
}

void Error_Handler(void)
{
  __disable_irq();
  while (1)
  {
  }
}
